# MSPM0L130X register map
Vendor: Texas Instruments; File version: This preliminary header file does not have a version number - build date: 2024-04-29 21:56:11
ARM Device
CPU: CM0 r0p1, little endian, MPU, no FPU, 3 interrupt priority bits
Registers are 32-bit, read-write, reset 0x0 unless marked. A register's access mark holds for its fields unless they carry their own. Offsets are from the block's base; lines under a group give offsets from that group; [hi:lo] are bit positions; {n}, {i} and the like mark numbered series; 'fields as' and 'values as' point back to an identical list; <NAME> marks a mode.

## Memory map
0x00000000 FLASH size 0x10000 — MEM
0x20000000 SYSMEM size 0x1000 — MEM
0x40004000 ADC0 size 0x2000 — PERIPHERALREGION
0x40008000 COMP0 size 0x1F00 — PERIPHERALREGION
0x40020000 OPA0 size 0x1F00 — PERIPHERALREGION
0x40022000 OPA1 size 0x1F00 — PERIPHERALREGION
0x40030000 VREF size 0x1F00 — PERIPHERALREGION
0x40080000 WWDT0 size 0x1500 — WWDT
0x40084000 TIMG0 size 0x1F00 — PERIPHERALREGION
0x40086000 TIMG1 size 0x1F00 — PERIPHERALREGION
0x40088000 TIMG2 size 0x1F00 — PERIPHERALREGION
0x4008C000 TIMG4 size 0x1F00 — PERIPHERALREGION
0x400A0000 GPIOA size 0x1F00 — PERIPHERALREGION
0x400AF000 SYSCTL size 0x2C64 — mem_map
0x400C7000 DEBUGSS size 0x1F00 — DSSM
0x400C9000 EVENTLP size 0x3000 — PERIPHERALREGION
0x400CD000 FLASHCTL size 0x2000 — F65NW
0x400F0000 I2C0 size 0x1F00 — PERIPHERALREGION
0x400F2000 I2C1 size 0x1F00 — PERIPHERALREGION
0x40100000 UART1 size 0x1F00 — PERIPHERALREGION
0x40108000 UART0 size 0x1F00 — PERIPHERALREGION
0x40400000 CPUSS size 0x1F00 — CPUSSMMR
0x40424000 WUC size 0x500 — PERIPHERALREGION
0x40428000 IOMUX size 0x2000 — PERIPHERALREGION
0x4042A000 DMA size 0x1F00 — PERIPHERALREGION
0x40440000 CRC size 0x2000 — PERIPHERALREGION
0x40468000 SPI0 size 0x1F00 — PERIPHERALREGION
0x4055A000 ADC0_SVT size 0x1000 — PERIPHERALREGIONSVT

## VREF — PERIPHERALREGION
Base 0x40030000
{0x800+0x18*i} VREF_GPRCM[{i}] (i=0..0) group
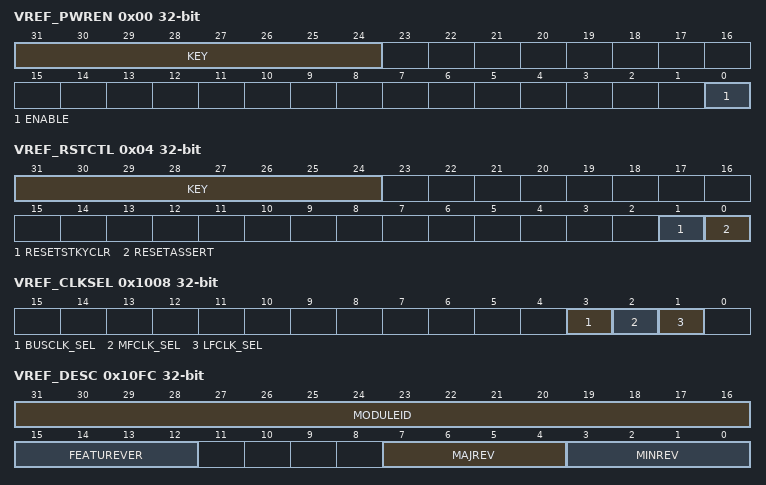
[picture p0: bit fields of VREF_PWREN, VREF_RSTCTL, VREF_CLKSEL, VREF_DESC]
  0x00 VREF_PWREN — Power enable
    [31:24] KEY wo — KEY to allow Power State Change
      38=KEY (KEY to allow write access to this register)
    [0] ENABLE — Enable the power
      0=DISABLE (Disable Power); 1=ENABLE (Enable Power)
  0x04 VREF_RSTCTL wo — Reset Control
    [31:24] KEY — KEY to allow Reset
      177=KEY (KEY to allow write access to this register)
    [1] RESETSTKYCLR — Clear the RESETSTKY bit in the STAT register
      0=NOP (Writing 0 has no effect); 1=CLR (Clear reset sticky bit)
    [0] RESETASSERT — Assert reset to the peripheral
      0=NOP (Writing 0 has no effect); 1=ASSERT (Assert reset)
  0x14 VREF_STAT ro — Status Register
    [16] RESETSTKY — This bit indicates, if the peripheral was reset, since this bit was cleared by RESETSTKYCLR in the RSTCTL register
      0=NORES (The peripheral has not been reset since this bit was last cleared by RESETSTKYCLR in the RSTCTL register); 1=RESET (The peripheral was reset since the last bit clear)
0x1000 VREF_CLKDIV — Clock Divider
  [2:0] RATIO — Selects divide ratio of module clock
0x1008 VREF_CLKSEL — Clock Selection
  [3] BUSCLK_SEL — Selects BUSCLK as clock source if enabled
  [2] MFCLK_SEL — Selects MFCLK as clock source if enabled
  [1] LFCLK_SEL — Selects LFCLK as clock source if enabled
0x10FC VREF_DESC ro — Module Description
  [31:16] MODULEID — Module identification contains a unique peripheral identification number. The assignments are maintained in a central database for all of the platform modules to ensure uniqueness.
  [15:12] FEATUREVER — Feature Set for the module *instance*
  [7:4] MAJREV — Major rev of the IP
  [3:0] MINREV — Minor rev of the IP
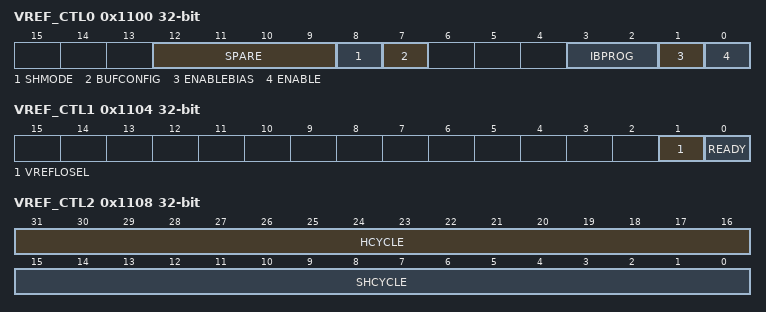
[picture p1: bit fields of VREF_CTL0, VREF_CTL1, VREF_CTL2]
0x1100 VREF_CTL0 — Control 0
  [12:9] SPARE — These bits are reserved
  [8] SHMODE — This bit enable sample and hold mode
    0=DISABLE (Sample and hold mode is disable); 1=Enable (Sample and hold mode is enable)
  [7] BUFCONFIG — These bits configure output buffer.
    0=OUTPUT2P5V (Configure Output Buffer to 2.5v); 1=OUTPUT1P4V (Configure Output Buffer to 1.4v)
  [3:2] IBPROG — There bits configure current bias.
    0=NOMIBIAS (Nominal Ibias setting.); 1=Ibias Program Option b01: TheFlash: Increase Ibias by 30% LordBusiness: Reduce Ibias by 50%; 2=Ibias Program Option b10: TheFlash: Reduce Ibias by 35% LordBusiness: Increase Ibias by 50%; 3=Ibias Program Option b11: TheFlash: Nominal Ibias LordBusiness: Reduce Ibias by 33%
  [1] ENABLEBIAS — This bit enables the VREF Bias.
    0=DISABLE (IBIAS is disable); 1=ENABLE (IBIAS is enable)
  [0] ENABLE — This bit enables the VREF module.
    0=DISABLE (VREF is disabled); 1=ENABLE (VREF is enabled)
0x1104 VREF_CTL1 — Control 1
  [1] VREFLOSEL — This bit select VREFLO pin
  [0] READY ro — These bits defines status of VREF
    0=NOTRDY (VREF output is not ready); 1=RDY (VREF output is ready)
0x1108 VREF_CTL2 — Control 2
  [31:16] HCYCLE — Hold cycle count
  [15:0] SHCYCLE — Sample and hold cycle count

## Licence text in the file
Copyright (C) 2024 Texas Instruments Incorporated - http://www.ti.com/ Redistribution and use in source and binary forms, with or without modification, are permitted provided that the following conditions are met: Redistributions of source code must retain the above copyright notice, this list of conditions and the following disclaimer. Redistributions in binary form must reproduce the above copyright notice, this list of conditions and the following disclaimer in the documentation and/or other materials provided with the distribution. Neither the name of Texas Instruments Incorporated nor the names of its contributors may be used to endorse or promote products derived from this software without specific prior written permission. THIS SOFTWARE IS PROVIDED BY THE COPYRIGHT HOLDERS AND CONTRIBUTORS "AS IS" AND ANY EXPRESS OR IMPLIED WARRANTIES, INCLUDING, BUT NOT LIMITED TO, THE IMPLIED WARRANTIES OF MERCHANTABILITY AND FITNESS FOR A PARTICULAR PURPOSE ARE DISCLAIMED. IN NO EVENT SHALL THE COPYRIGHT OWNER OR CONTRIBUTORS BE LIABLE FOR ANY DIRECT, INDIRECT, INCIDENTAL, SPECIAL, EXEMPLARY, OR CONSEQUENTIAL DAMAGES (INCLUDING, BUT NOT LIMITED TO, PROCUREMENT OF SUBSTITUTE GOODS OR SERVICES; LOSS OF USE, DATA, OR PROFITS; OR BUSINESS INTERRUPTION) HOWEVER CAUSED AND ON ANY THEORY OF LIABILITY, WHETHER IN CONTRACT, STRICT LIABILITY, OR TORT (INCLUDING NEGLIGENCE OR OTHERWISE) ARISING IN ANY WAY OUT OF THE USE OF THIS SOFTWARE, EVEN IF ADVISED OF THE POSSIBILITY OF SUCH DAMAGE.
